# cslr_vpbe_001 register map
Vendor: Texas Instruments
Peripheral module from a debugger description file.
Registers are 32-bit, access per field, reset 0x0 unless marked. A register's access mark holds for its fields unless they carry their own. Offsets are as the file gives them; lines under a group give offsets from that group; [hi:lo] are bit positions; {n}, {i} and the like mark numbered series; 'fields as' and 'values as' point back to an identical list; <NAME> marks a mode.

## VPBE — Video Processor Back End - top-level registers (spec version: 1.00.w.02a)
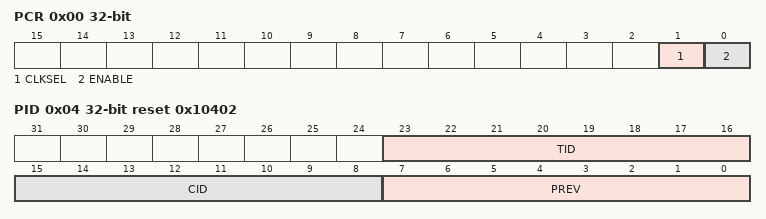
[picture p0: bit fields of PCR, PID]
0x00 PCR — Peripheral Control Register
  [1] CLKSEL rw — Clock Select
    0=FULL (Use Video Encoder Clock selected in SYSTEM module); 1=HALF (Use 1/2 Video Encoder Clock selected in SYSTEM module)
  [0] ENABLE rw — VPBE Enable
    0=DISABLE; 1=ENABLE
0x04 PID ro reset 0x10402 — Peripheral Revision and Class Information
  [23:16] TID — Peripheral Identification VPBE module
  [15:8] CID — Class Identification
  [7:0] PREV — Peripheral Revision Number Initial Revision
